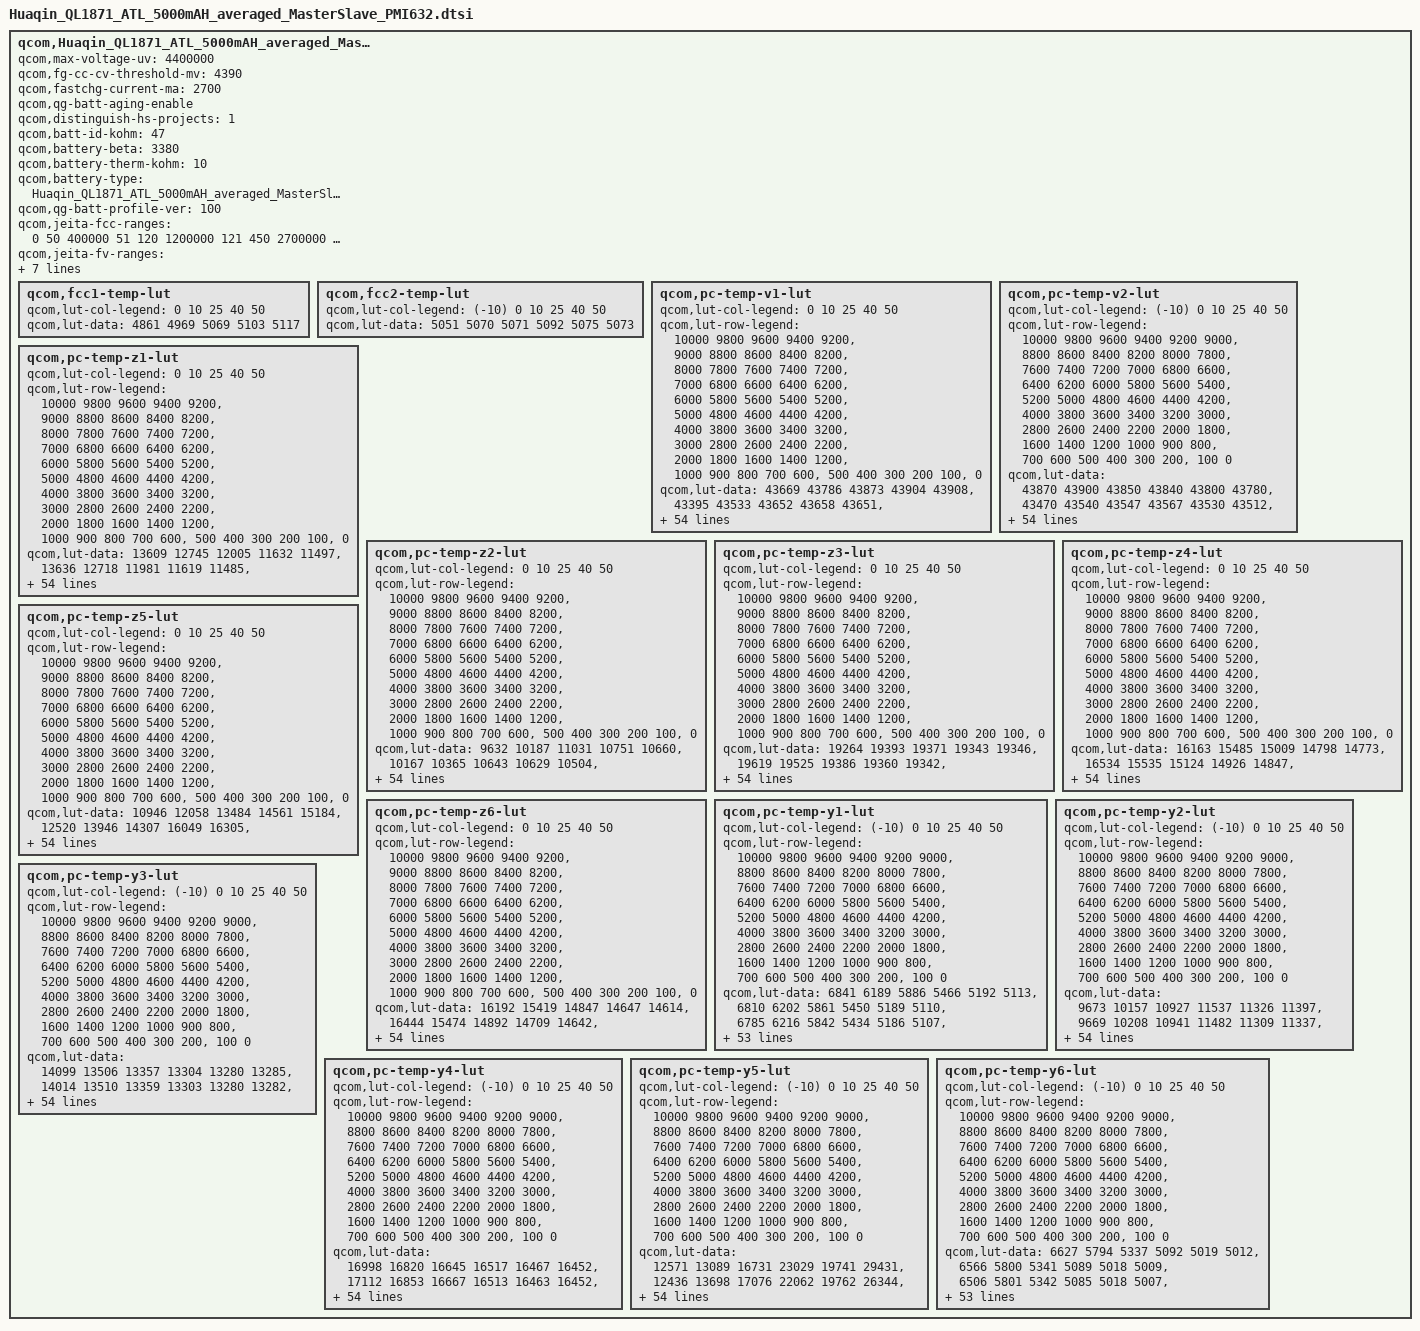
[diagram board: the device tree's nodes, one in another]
qcom,Huaqin_QL1871_ATL_5000mAH_averaged_MasterSlave_PMI632 {
        /* Huaqin_QL1871_ATL_5000mAH_averaged_MasterSlave_PMI632 */
	qcom,max-voltage-uv = <4400000>;
	qcom,fg-cc-cv-threshold-mv = <4390>;
	qcom,fastchg-current-ma = <2700>;
	/* HS60 add for SR-ZQL1695-01-357 Import battery aging by gaochao at 2019/08/29 start */
	qcom,qg-batt-aging-enable;
	/* HS60 add for SR-ZQL1695-01-357 Import battery aging by gaochao at 2019/08/29 end */
	/* HS50 add for SR-QL3095-01-67 Distinguish HS60, HS70 and HS50 charging by wenyaqi at 2020/8/3 start */
	qcom,distinguish-hs-projects = <1>;
	/* HS50 add for SR-QL3095-01-67 Distinguish HS60, HS70 and HS50 charging by wenyaqi at 2020/8/3 end */
	qcom,batt-id-kohm = <47>;
	qcom,battery-beta = <3380>;
	qcom,battery-therm-kohm = <10>;
	qcom,battery-type = "Huaqin_QL1871_ATL_5000mAH_averaged_MasterSlave_PMI632";
	qcom,qg-batt-profile-ver = <100>;

	qcom,jeita-fcc-ranges = <0   50   400000
				 51   120   1200000
				 121 450  2700000
				 451 500  2200000>;
	qcom,jeita-fv-ranges =  <0   50  4400000
				 51   120  4400000
				 121 450  4400000
				 451 500  4200000>;

	/* HS60 add for SR-ZQL1695-01-357 Import battery aging by gaochao at 2019/08/29 start */
	qcom,vfloat-ranges = <0 299 4400000
	                      300 399 4380000
                              400 699 4360000
                              700 999 4340000
                              1000 9999 4290000>;

	qcom,vbat-rechg-ranges = <0 299 4330000
                                  300 399 4310000
                                  400 699 4290000
                                  700 999 4270000
                                  1000 9999 4220000>;
	/* HS60 add for SR-ZQL1695-01-357 Import battery aging by gaochao at 2019/08/29 end */

	/* COOL = 15 DegC, WARM = 45 DegC */
	qcom,jeita-soft-thresholds = <0x2554 0xFDC>;
	/* COLD = 0 DegC, HOT = 50 DegC */
	/* Huaqin add for HS70-733 modify jeita-hard-thresholds to 50 by qianyingdong at 2019/11/26 start */
	qcom,jeita-hard-thresholds = <0x36B9 0xDBF>;
	/* Huaqin add for HS70-733 modify jeita-hard-thresholds to 50 by qianyingdong at 2019/11/26 end */

	qcom,fcc1-temp-lut {
		qcom,lut-col-legend = <0 10 25 40 50>;
		qcom,lut-data = <4861 4969 5069 5103 5117>;
	};

	qcom,fcc2-temp-lut {
		qcom,lut-col-legend = <(-10) 0 10 25 40 50>;
		qcom,lut-data = <5051 5070 5071 5092 5075 5073>;
	};

	qcom,pc-temp-v1-lut {
		qcom,lut-col-legend = <0 10 25 40 50>;
		qcom,lut-row-legend = <10000 9800 9600 9400 9200>,
			<9000 8800 8600 8400 8200>,
			<8000 7800 7600 7400 7200>,
			<7000 6800 6600 6400 6200>,
			<6000 5800 5600 5400 5200>,
			<5000 4800 4600 4400 4200>,
			<4000 3800 3600 3400 3200>,
			<3000 2800 2600 2400 2200>,
			<2000 1800 1600 1400 1200>,
			<1000 900 800 700 600>,
			<500 400 300 200 100>,
			<0>;
		qcom,lut-data = <43669 43786 43873 43904 43908>,
			<43395 43533 43652 43658 43651>,
			<43131 43284 43407 43424 43418>,
			<42875 43040 43157 43190 43187>,
			<42628 42800 42914 42954 42956>,
			<42391 42562 42672 42713 42722>,
			<42161 42325 42432 42475 42489>,
			<41938 42091 42194 42239 42253>,
			<41720 41862 41960 42006 42018>,
			<41510 41638 41728 41775 41786>,
			<41314 41422 41500 41545 41557>,
			<41121 41221 41281 41322 41333>,
			<40910 41021 41068 41104 41114>,
			<40682 40810 40862 40893 40903>,
			<40461 40591 40653 40686 40695>,
			<40250 40388 40451 40485 40494>,
			<40051 40198 40264 40293 40301>,
			<39887 40023 40091 40112 40117>,
			<39754 39868 39926 39939 39942>,
			<39627 39729 39779 39781 39780>,
			<39491 39583 39630 39630 39628>,
			<39352 39423 39428 39445 39448>,
			<39220 39254 39163 39202 39212>,
			<39094 39061 38951 38981 38990>,
			<38971 38844 38813 38827 38830>,
			<38848 38691 38701 38700 38697>,
			<38725 38606 38598 38585 38579>,
			<38615 38540 38505 38481 38473>,
			<38514 38477 38421 38388 38378>,
			<38426 38417 38346 38303 38292>,
			<38366 38364 38280 38228 38214>,
			<38321 38316 38221 38160 38142>,
			<38284 38271 38169 38100 38076>,
			<38254 38234 38126 38048 38016>,
			<38228 38203 38094 38008 37967>,
			<38203 38171 38061 37970 37919>,
			<38183 38142 38023 37922 37860>,
			<38157 38110 37981 37865 37791>,
			<38111 38056 37923 37797 37715>,
			<38040 37965 37833 37716 37634>,
			<37951 37857 37727 37620 37542>,
			<37824 37734 37614 37508 37432>,
			<37677 37592 37484 37376 37302>,
			<37512 37424 37325 37218 37144>,
			<37354 37271 37173 37078 37006>,
			<37238 37164 37076 36987 36922>,
			<37199 37131 37047 36960 36895>,
			<37169 37111 37026 36943 36879>,
			<37138 37086 37006 36924 36860>,
			<37091 37048 36967 36874 36798>,
			<36890 36825 36720 36609 36513>,
			<36442 36385 36283 36167 36068>,
			<35864 35806 35705 35588 35486>,
			<35076 35012 34913 34795 34689>,
			<33832 33775 33677 33560 33448>,
			<30000 30000 30000 30000 30000>;
	};

	qcom,pc-temp-v2-lut {
		qcom,lut-col-legend = <(-10) 0 10 25 40 50>;
		qcom,lut-row-legend = <10000 9800 9600 9400 9200 9000>,
			<8800 8600 8400 8200 8000 7800>,
			<7600 7400 7200 7000 6800 6600>,
			<6400 6200 6000 5800 5600 5400>,
			<5200 5000 4800 4600 4400 4200>,
			<4000 3800 3600 3400 3200 3000>,
			<2800 2600 2400 2200 2000 1800>,
			<1600 1400 1200 1000 900 800>,
			<700 600 500 400 300 200>,
			<100 0>;
		qcom,lut-data = <43870 43900 43850 43840 43800 43780>,
			<43470 43540 43547 43567 43530 43512>,
			<43102 43211 43261 43304 43270 43254>,
			<42766 42918 42994 43053 43023 43007>,
			<42456 42657 42745 42813 42788 42770>,
			<42184 42404 42501 42575 42554 42536>,
			<41958 42149 42257 42338 42319 42302>,
			<41750 41900 42017 42103 42084 42069>,
			<41509 41645 41783 41871 41852 41839>,
			<41233 41385 41553 41642 41623 41611>,
			<41015 41171 41329 41417 41397 41386>,
			<40893 41028 41112 41197 41176 41165>,
			<40774 40887 40900 40981 40958 40948>,
			<40513 40652 40700 40773 40749 40738>,
			<40045 40317 40509 40570 40544 40533>,
			<39685 40031 40307 40371 40348 40337>,
			<39485 39818 40088 40172 40158 40148>,
			<39319 39623 39865 39981 39975 39968>,
			<39138 39420 39645 39807 39805 39799>,
			<38958 39216 39426 39641 39643 39638>,
			<38791 39026 39221 39445 39457 39455>,
			<38632 38848 39024 39196 39223 39226>,
			<38492 38680 38845 38964 38996 39002>,
			<38381 38510 38692 38790 38816 38819>,
			<38288 38348 38555 38642 38658 38658>,
			<38209 38236 38431 38516 38525 38523>,
			<38143 38159 38319 38408 38415 38411>,
			<38083 38096 38214 38309 38316 38311>,
			<38023 38039 38111 38217 38224 38218>,
			<37964 37989 38014 38131 38139 38133>,
			<37908 37940 37942 38053 38064 38056>,
			<37852 37893 37885 37979 37996 37987>,
			<37796 37847 37837 37912 37931 37921>,
			<37737 37801 37797 37850 37868 37858>,
			<37677 37755 37761 37792 37806 37794>,
			<37614 37704 37722 37732 37728 37709>,
			<37548 37647 37683 37669 37634 37594>,
			<37479 37585 37637 37603 37540 37484>,
			<37411 37516 37576 37532 37458 37395>,
			<37342 37440 37502 37456 37378 37312>,
			<37274 37355 37416 37373 37293 37226>,
			<37208 37258 37308 37278 37204 37138>,
			<37138 37148 37174 37158 37090 37025>,
			<37062 37029 37022 37020 36958 36893>,
			<36979 36917 36891 36892 36837 36779>,
			<36880 36823 36799 36848 36801 36742>,
			<36819 36782 36760 36831 36788 36733>,
			<36746 36739 36721 36806 36773 36718>,
			<36656 36685 36664 36767 36740 36685>,
			<36512 36596 36565 36647 36629 36558>,
			<36267 36399 36292 36290 36294 36193>,
			<35871 35992 35787 35749 35769 35669>,
			<35282 35376 35114 35043 35088 34982>,
			<34393 34494 34145 34028 34114 34000>,
			<32803 33138 32773 32593 32889 32727>,
			<28390 27880 27663 27615 27964 27918>;
	};

	qcom,pc-temp-z1-lut {
		qcom,lut-col-legend = <0 10 25 40 50>;
		qcom,lut-row-legend = <10000 9800 9600 9400 9200>,
			<9000 8800 8600 8400 8200>,
			<8000 7800 7600 7400 7200>,
			<7000 6800 6600 6400 6200>,
			<6000 5800 5600 5400 5200>,
			<5000 4800 4600 4400 4200>,
			<4000 3800 3600 3400 3200>,
			<3000 2800 2600 2400 2200>,
			<2000 1800 1600 1400 1200>,
			<1000 900 800 700 600>,
			<500 400 300 200 100>,
			<0>;
		qcom,lut-data = <13609 12745 12005 11632 11497>,
			<13636 12718 11981 11619 11485>,
			<13626 12696 11971 11606 11478>,
			<13599 12680 11965 11596 11472>,
			<13577 12666 11958 11590 11468>,
			<13560 12662 11950 11586 11466>,
			<13544 12665 11942 11583 11464>,
			<13525 12669 11932 11580 11462>,
			<13503 12671 11925 11577 11461>,
			<13493 12672 11921 11575 11460>,
			<13494 12672 11918 11573 11459>,
			<13497 12667 11916 11572 11459>,
			<13490 12662 11915 11570 11459>,
			<13470 12659 11914 11569 11459>,
			<13458 12653 11910 11567 11458>,
			<13461 12650 11906 11565 11458>,
			<13470 12649 11906 11565 11457>,
			<13477 12649 11906 11566 11458>,
			<13488 12655 11908 11566 11459>,
			<13500 12671 11910 11567 11461>,
			<13512 12682 11914 11570 11463>,
			<13525 12690 11917 11572 11465>,
			<13533 12696 11921 11576 11468>,
			<13539 12696 11925 11580 11471>,
			<13544 12688 11932 11583 11473>,
			<13556 12687 11940 11587 11477>,
			<13575 12705 11945 11591 11480>,
			<13586 12725 11949 11595 11484>,
			<13594 12728 11953 11599 11487>,
			<13601 12726 11957 11603 11490>,
			<13601 12726 11962 11607 11493>,
			<13599 12730 11965 11611 11495>,
			<13597 12734 11969 11615 11498>,
			<13593 12736 11973 11619 11501>,
			<13589 12738 11978 11622 11504>,
			<13588 12740 11983 11625 11507>,
			<13600 12748 11988 11630 11511>,
			<13611 12759 11993 11636 11516>,
			<13607 12764 11999 11640 11520>,
			<13598 12768 12004 11644 11524>,
			<13601 12771 12009 11647 11527>,
			<13635 12771 12013 11650 11530>,
			<13647 12773 12017 11654 11531>,
			<13588 12782 12023 11658 11533>,
			<13624 12799 12030 11661 11535>,
			<13633 12798 12032 11663 11536>,
			<13623 12798 12035 11664 11536>,
			<13621 12793 12034 11667 11538>,
			<13632 12800 12042 11668 11540>,
			<13661 12799 12042 11674 11545>,
			<13646 12828 12057 11683 11554>,
			<13661 12842 12072 11692 11562>,
			<13681 12878 12088 11704 11572>,
			<13740 12917 12119 11726 11589>,
			<13740 12917 12119 11726 11589>,
			<13740 12917 12119 11726 11589>;
	};

	qcom,pc-temp-z2-lut {
		qcom,lut-col-legend = <0 10 25 40 50>;
		qcom,lut-row-legend = <10000 9800 9600 9400 9200>,
			<9000 8800 8600 8400 8200>,
			<8000 7800 7600 7400 7200>,
			<7000 6800 6600 6400 6200>,
			<6000 5800 5600 5400 5200>,
			<5000 4800 4600 4400 4200>,
			<4000 3800 3600 3400 3200>,
			<3000 2800 2600 2400 2200>,
			<2000 1800 1600 1400 1200>,
			<1000 900 800 700 600>,
			<500 400 300 200 100>,
			<0>;
		qcom,lut-data = <9632 10187 11031 10751 10660>,
			<10167 10365 10643 10629 10504>,
			<10260 10462 10653 10671 10541>,
			<10299 10447 10670 10718 10599>,
			<10335 10399 10683 10726 10607>,
			<10378 10382 10697 10725 10553>,
			<10410 10394 10705 10722 10505>,
			<10418 10411 10713 10709 10490>,
			<10412 10424 10720 10692 10482>,
			<10398 10436 10729 10684 10481>,
			<10356 10447 10739 10679 10485>,
			<10305 10456 10743 10671 10495>,
			<10276 10465 10740 10643 10529>,
			<10252 10473 10738 10612 10566>,
			<10241 10483 10738 10608 10564>,
			<10242 10495 10738 10616 10543>,
			<10244 10517 10741 10620 10530>,
			<10252 10539 10748 10616 10529>,
			<10284 10548 10752 10609 10531>,
			<10312 10553 10742 10597 10530>,
			<10318 10554 10728 10582 10529>,
			<10321 10533 10725 10590 10535>,
			<10323 10504 10723 10687 10577>,
			<10325 10484 10714 10760 10613>,
			<10325 10458 10678 10686 10573>,
			<10323 10446 10637 10558 10483>,
			<10317 10442 10625 10538 10437>,
			<10316 10437 10620 10573 10415>,
			<10321 10436 10618 10606 10405>,
			<10330 10435 10624 10623 10413>,
			<10340 10435 10635 10636 10430>,
			<10353 10450 10655 10640 10444>,
			<10367 10474 10689 10629 10456>,
			<10384 10494 10709 10622 10470>,
			<10402 10514 10720 10631 10504>,
			<10383 10534 10727 10650 10552>,
			<10204 10555 10739 10675 10608>,
			<10071 10576 10763 10714 10675>,
			<10135 10593 10785 10757 10700>,
			<10325 10609 10832 10818 10686>,
			<10721 10616 10866 10861 10670>,
			<12327 10612 10865 10854 10671>,
			<13431 10607 10860 10839 10678>,
			<12784 10607 10854 10861 10688>,
			<13949 10625 10855 10851 10690>,
			<14915 10651 10867 10806 10655>,
			<15695 10663 10838 10785 10693>,
			<15862 10973 10864 10815 10713>,
			<14521 10840 10847 10820 10736>,
			<14391 11070 11035 10893 10804>,
			<14562 11062 10989 10855 10593>,
			<13524 10968 10939 10746 10499>,
			<13135 10648 10833 10721 10446>,
			<11894 10622 10747 10612 10327>,
			<11894 10622 10747 10612 10327>,
			<11894 10622 10747 10612 10327>;
	};

	qcom,pc-temp-z3-lut {
		qcom,lut-col-legend = <0 10 25 40 50>;
		qcom,lut-row-legend = <10000 9800 9600 9400 9200>,
			<9000 8800 8600 8400 8200>,
			<8000 7800 7600 7400 7200>,
			<7000 6800 6600 6400 6200>,
			<6000 5800 5600 5400 5200>,
			<5000 4800 4600 4400 4200>,
			<4000 3800 3600 3400 3200>,
			<3000 2800 2600 2400 2200>,
			<2000 1800 1600 1400 1200>,
			<1000 900 800 700 600>,
			<500 400 300 200 100>,
			<0>;
		qcom,lut-data = <19264 19393 19371 19343 19346>,
			<19619 19525 19386 19360 19342>,
			<19714 19608 19434 19375 19356>,
			<19766 19631 19461 19383 19363>,
			<19775 19643 19458 19384 19364>,
			<19733 19645 19449 19383 19358>,
			<19691 19627 19441 19380 19354>,
			<19689 19606 19433 19375 19353>,
			<19696 19594 19427 19368 19353>,
			<19701 19585 19426 19364 19352>,
			<19716 19575 19425 19362 19351>,
			<19732 19564 19422 19360 19349>,
			<19732 19554 19414 19353 19345>,
			<19719 19548 19408 19347 19340>,
			<19709 19545 19406 19346 19338>,
			<19704 19539 19404 19346 19337>,
			<19695 19524 19400 19347 19336>,
			<19682 19511 19387 19346 19336>,
			<19647 19509 19379 19345 19335>,
			<19622 19510 19379 19345 19334>,
			<19623 19511 19379 19346 19332>,
			<19628 19521 19387 19349 19333>,
			<19633 19535 19419 19367 19350>,
			<19637 19548 19436 19381 19365>,
			<19643 19561 19438 19378 19365>,
			<19655 19566 19439 19374 19363>,
			<19677 19567 19439 19373 19362>,
			<19691 19567 19437 19375 19361>,
			<19700 19566 19435 19376 19359>,
			<19707 19560 19433 19375 19354>,
			<19704 19556 19431 19373 19347>,
			<19692 19551 19429 19371 19345>,
			<19677 19544 19426 19368 19343>,
			<19664 19536 19421 19365 19342>,
			<19647 19527 19412 19357 19338>,
			<19611 19521 19404 19350 19335>,
			<19515 19515 19402 19349 19335>,
			<19440 19510 19402 19349 19335>,
			<19388 19506 19402 19349 19336>,
			<19295 19502 19400 19348 19336>,
			<19261 19499 19398 19347 19335>,
			<19258 19498 19395 19347 19333>,
			<19257 19496 19391 19347 19331>,
			<19258 19493 19387 19350 19338>,
			<19257 19475 19385 19347 19341>,
			<19257 19463 19375 19339 19332>,
			<19257 19453 19372 19336 19330>,
			<19257 19359 19370 19327 19318>,
			<19257 19321 19367 19327 19315>,
			<19257 19262 19335 19321 19316>,
			<19257 19330 19357 19329 19331>,
			<19257 19294 19354 19330 19333>,
			<19257 19300 19352 19335 19337>,
			<19258 19354 19357 19333 19343>,
			<19258 19354 19357 19333 19343>,
			<19258 19354 19357 19333 19343>;
	};

	qcom,pc-temp-z4-lut {
		qcom,lut-col-legend = <0 10 25 40 50>;
		qcom,lut-row-legend = <10000 9800 9600 9400 9200>,
			<9000 8800 8600 8400 8200>,
			<8000 7800 7600 7400 7200>,
			<7000 6800 6600 6400 6200>,
			<6000 5800 5600 5400 5200>,
			<5000 4800 4600 4400 4200>,
			<4000 3800 3600 3400 3200>,
			<3000 2800 2600 2400 2200>,
			<2000 1800 1600 1400 1200>,
			<1000 900 800 700 600>,
			<500 400 300 200 100>,
			<0>;
		qcom,lut-data = <16163 15485 15009 14798 14773>,
			<16534 15535 15124 14926 14847>,
			<16475 15545 15076 14897 14840>,
			<16286 15473 15011 14845 14809>,
			<16109 15278 14955 14820 14793>,
			<15951 15140 14900 14808 14786>,
			<15795 15058 14867 14798 14780>,
			<15639 14999 14848 14788 14772>,
			<15481 14961 14833 14780 14765>,
			<15363 14932 14816 14771 14758>,
			<15284 14914 14801 14763 14751>,
			<15223 14902 14791 14755 14744>,
			<15173 14892 14785 14749 14737>,
			<15132 14878 14778 14743 14729>,
			<15099 14863 14770 14735 14722>,
			<15073 14851 14762 14726 14716>,
			<15050 14843 14756 14717 14709>,
			<15033 14836 14751 14709 14701>,
			<15020 14822 14746 14702 14694>,
			<15007 14802 14740 14695 14688>,
			<14991 14795 14734 14690 14683>,
			<14973 14809 14770 14700 14687>,
			<14962 14836 14918 14789 14755>,
			<14956 14901 14994 14856 14813>,
			<14951 15029 14952 14844 14806>,
			<14952 15086 14890 14816 14785>,
			<14963 15034 14854 14795 14771>,
			<14973 14959 14829 14778 14760>,
			<14985 14916 14811 14764 14751>,
			<14997 14884 14799 14753 14743>,
			<14995 14862 14790 14744 14735>,
			<14978 14847 14784 14738 14728>,
			<14959 14836 14780 14734 14720>,
			<14943 14828 14774 14729 14714>,
			<14928 14821 14765 14721 14706>,
			<14932 14815 14759 14715 14700>,
			<15001 14805 14759 14720 14705>,
			<15056 14797 14760 14734 14726>,
			<15091 14797 14763 14741 14735>,
			<15169 14803 14772 14742 14733>,
			<15195 14806 14779 14743 14731>,
			<15192 14796 14768 14738 14725>,
			<15188 14786 14752 14729 14717>,
			<15184 14785 14754 14735 14728>,
			<15151 14778 14750 14736 14732>,
			<15130 14757 14727 14717 14706>,
			<15120 14752 14711 14706 14695>,
			<15104 14831 14691 14689 14682>,
			<15091 14858 14676 14663 14657>,
			<15078 14911 14699 14666 14657>,
			<15076 14858 14707 14692 14682>,
			<15114 14910 14715 14697 14688>,
			<15134 14910 14721 14694 14686>,
			<15163 14871 14721 14698 14682>,
			<15163 14871 14721 14698 14682>,
			<15163 14871 14721 14698 14682>;
	};

	qcom,pc-temp-z5-lut {
		qcom,lut-col-legend = <0 10 25 40 50>;
		qcom,lut-row-legend = <10000 9800 9600 9400 9200>,
			<9000 8800 8600 8400 8200>,
			<8000 7800 7600 7400 7200>,
			<7000 6800 6600 6400 6200>,
			<6000 5800 5600 5400 5200>,
			<5000 4800 4600 4400 4200>,
			<4000 3800 3600 3400 3200>,
			<3000 2800 2600 2400 2200>,
			<2000 1800 1600 1400 1200>,
			<1000 900 800 700 600>,
			<500 400 300 200 100>,
			<0>;
		qcom,lut-data = <10946 12058 13484 14561 15184>,
			<12520 13946 14307 16049 16305>,
			<13244 15353 16099 17697 18134>,
			<13726 16179 17514 18859 19684>,
			<13939 16761 18248 19391 19944>,
			<14012 17255 18754 19723 19396>,
			<14076 17775 18859 19837 19004>,
			<14237 18202 18825 19460 19226>,
			<14561 18489 18799 18970 19654>,
			<14867 18760 19124 18937 19934>,
			<15136 18832 19715 19027 20161>,
			<15387 18648 19767 19049 20252>,
			<15570 18460 19220 18426 19832>,
			<15727 18688 18843 17747 19284>,
			<15811 19358 19059 17934 19279>,
			<15963 19608 19403 18614 19558>,
			<16190 18988 19261 18948 19937>,
			<16151 18317 18228 19378 20635>,
			<15677 18490 17606 19935 21429>,
			<15296 19405 17822 20726 22059>,
			<15502 20636 18326 21795 22631>,
			<16096 23060 19364 21913 22633>,
			<16681 25227 21550 20496 20747>,
			<17175 25177 22577 18965 18822>,
			<17799 24208 20900 17980 18180>,
			<19076 23299 18842 17213 17776>,
			<21280 22238 18843 17259 17821>,
			<22756 21331 19752 18333 18628>,
			<23858 21386 20808 19520 19189>,
			<24709 22064 22046 20440 19054>,
			<24413 22637 23388 21318 18839>,
			<23267 23516 24734 22241 18978>,
			<22095 24546 26087 23344 19926>,
			<21168 24883 26460 23814 20989>,
			<20118 24715 25661 23505 22181>,
			<18736 24580 24893 23142 23135>,
			<16645 24448 25262 23352 23215>,
			<15134 24259 26229 23966 23147>,
			<13963 24209 26574 24162 23041>,
			<12001 24147 26415 23422 22795>,
			<11317 24134 26085 22703 22428>,
			<11316 24279 25543 22841 21705>,
			<11314 24387 24673 23134 20848>,
			<11306 23741 23080 22789 21764>,
			<11283 21329 22783 21189 21824>,
			<11243 20015 21167 19578 19418>,
			<11211 19016 21235 19417 19334>,
			<11163 13368 21589 18577 17923>,
			<11160 12708 21905 20752 20105>,
			<11175 11405 16341 19634 20451>,
			<11221 12559 17918 17018 18558>,
			<11188 11885 16921 16520 17502>,
			<11112 11861 16132 16497 17348>,
			<11014 12520 15997 15564 17178>,
			<11014 12520 15997 15564 17178>,
			<11014 12520 15997 15564 17178>;
	};

	qcom,pc-temp-z6-lut {
		qcom,lut-col-legend = <0 10 25 40 50>;
		qcom,lut-row-legend = <10000 9800 9600 9400 9200>,
			<9000 8800 8600 8400 8200>,
			<8000 7800 7600 7400 7200>,
			<7000 6800 6600 6400 6200>,
			<6000 5800 5600 5400 5200>,
			<5000 4800 4600 4400 4200>,
			<4000 3800 3600 3400 3200>,
			<3000 2800 2600 2400 2200>,
			<2000 1800 1600 1400 1200>,
			<1000 900 800 700 600>,
			<500 400 300 200 100>,
			<0>;
		qcom,lut-data = <16192 15419 14847 14647 14614>,
			<16444 15474 14892 14709 14642>,
			<16412 15488 14884 14700 14643>,
			<16303 15452 14871 14682 14635>,
			<16190 15350 14848 14671 14627>,
			<16066 15270 14813 14664 14621>,
			<15945 15215 14791 14657 14616>,
			<15849 15173 14777 14649 14611>,
			<15766 15145 14766 14642 14608>,
			<15713 15124 14757 14636 14604>,
			<15686 15108 14749 14631 14600>,
			<15665 15096 14741 14625 14596>,
			<15637 15085 14734 14619 14591>,
			<15603 15071 14727 14613 14585>,
			<15575 15056 14722 14608 14581>,
			<15559 15043 14717 14605 14577>,
			<15547 15032 14711 14601 14574>,
			<15533 15024 14702 14597 14570>,
			<15517 15019 14697 14593 14567>,
			<15506 15014 14695 14591 14564>,
			<15505 15013 14694 14589 14561>,
			<15505 15026 14714 14595 14564>,
			<15506 15050 14796 14645 14604>,
			<15509 15089 14839 14683 14639>,
			<15515 15155 14823 14677 14636>,
			<15526 15184 14799 14663 14626>,
			<15546 15165 14785 14655 14620>,
			<15562 15137 14774 14649 14615>,
			<15578 15120 14767 14644 14610>,
			<15590 15106 14761 14639 14604>,
			<15590 15097 14757 14634 14598>,
			<15582 15090 14754 14631 14593>,
			<15572 15084 14752 14628 14590>,
			<15563 15079 14748 14624 14586>,
			<15552 15074 14740 14617 14581>,
			<15542 15071 14735 14611 14577>,
			<15530 15069 14735 14613 14579>,
			<15522 15067 14737 14620 14589>,
			<15519 15069 14739 14624 14593>,
			<15516 15076 14744 14625 14593>,
			<15517 15080 14748 14625 14592>,
			<15524 15081 14743 14623 14589>,
			<15531 15082 14736 14620 14585>,
			<15539 15086 14738 14625 14594>,
			<15536 15082 14737 14625 14597>,
			<15534 15074 14723 14613 14582>,
			<15533 15069 14716 14606 14576>,
			<15528 15059 14707 14594 14565>,
			<15527 15056 14701 14584 14552>,
			<15530 15057 14697 14583 14554>,
			<15545 15078 14716 14600 14574>,
			<15578 15095 14722 14606 14580>,
			<15612 15113 14729 14610 14584>,
			<15662 15146 14740 14615 14589>,
			<15662 15146 14740 14615 14589>,
			<15662 15146 14740 14615 14589>;
	};

	qcom,pc-temp-y1-lut {
		qcom,lut-col-legend = <(-10) 0 10 25 40 50>;
		qcom,lut-row-legend = <10000 9800 9600 9400 9200 9000>,
			<8800 8600 8400 8200 8000 7800>,
			<7600 7400 7200 7000 6800 6600>,
			<6400 6200 6000 5800 5600 5400>,
			<5200 5000 4800 4600 4400 4200>,
			<4000 3800 3600 3400 3200 3000>,
			<2800 2600 2400 2200 2000 1800>,
			<1600 1400 1200 1000 900 800>,
			<700 600 500 400 300 200>,
			<100 0>;
		qcom,lut-data = <6841 6189 5886 5466 5192 5113>,
			<6810 6202 5861 5450 5189 5110>,
			<6785 6216 5842 5434 5186 5107>,
			<6768 6230 5828 5420 5182 5105>,
			<6758 6240 5820 5408 5179 5102>,
			<6755 6243 5817 5398 5176 5101>,
			<6771 6239 5822 5390 5173 5099>,
			<6793 6233 5829 5384 5170 5099>,
			<6790 6226 5825 5382 5168 5097>,
			<6767 6212 5808 5379 5166 5095>,
			<6754 6205 5795 5378 5164 5094>,
			<6764 6206 5785 5376 5161 5093>,
			<6775 6208 5777 5372 5159 5092>,
			<6766 6214 5779 5367 5158 5092>,
			<6750 6232 5787 5360 5158 5092>,
			<6745 6237 5791 5357 5157 5092>,
			<6775 6212 5796 5357 5157 5092>,
			<6809 6187 5802 5357 5156 5092>,
			<6806 6194 5804 5355 5156 5092>,
			<6786 6218 5809 5351 5156 5093>,
			<6777 6231 5809 5350 5156 5093>,
			<6779 6238 5801 5354 5158 5094>,
			<6781 6241 5795 5359 5159 5094>,
			<6782 6237 5799 5360 5160 5095>,
			<6784 6231 5808 5362 5161 5096>,
			<6782 6230 5811 5364 5162 5098>,
			<6774 6235 5806 5369 5164 5099>,
			<6767 6239 5802 5373 5167 5101>,
			<6761 6240 5807 5375 5171 5103>,
			<6751 6242 5815 5377 5174 5105>,
			<6740 6235 5815 5380 5177 5108>,
			<6718 6223 5801 5387 5180 5110>,
			<6701 6216 5790 5392 5182 5112>,
			<6708 6219 5798 5397 5186 5114>,
			<6724 6225 5813 5401 5189 5116>,
			<6729 6220 5825 5400 5192 5118>,
			<6726 6193 5838 5398 5195 5120>,
			<6722 6176 5845 5397 5197 5121>,
			<6735 6184 5845 5405 5199 5123>,
			<6759 6197 5845 5414 5201 5126>,
			<6757 6202 5840 5414 5203 5127>,
			<6718 6217 5823 5411 5205 5128>,
			<6704 6227 5819 5419 5208 5130>,
			<6703 6231 5822 5429 5211 5132>,
			<6731 6220 5844 5435 5217 5137>,
			<6757 6231 5854 5448 5223 5140>,
			<6776 6208 5860 5445 5223 5141>,
			<6774 6240 5833 5452 5224 5140>,
			<6690 6248 5847 5460 5225 5141>,
			<6714 6221 5842 5456 5224 5142>,
			<6735 6210 5850 5467 5227 5144>,
			<6767 6213 5854 5492 5236 5151>,
			<6734 6228 5888 5508 5249 5160>,
			<6770 6251 5903 5534 5262 5171>,
			<6770 6251 5903 5534 5262 5171>,
			<6770 6251 5903 5534 5262 5171>;
	};

	qcom,pc-temp-y2-lut {
		qcom,lut-col-legend = <(-10) 0 10 25 40 50>;
		qcom,lut-row-legend = <10000 9800 9600 9400 9200 9000>,
			<8800 8600 8400 8200 8000 7800>,
			<7600 7400 7200 7000 6800 6600>,
			<6400 6200 6000 5800 5600 5400>,
			<5200 5000 4800 4600 4400 4200>,
			<4000 3800 3600 3400 3200 3000>,
			<2800 2600 2400 2200 2000 1800>,
			<1600 1400 1200 1000 900 800>,
			<700 600 500 400 300 200>,
			<100 0>;
		qcom,lut-data = <9673 10157 10927 11537 11326 11397>,
			<9669 10208 10941 11482 11309 11337>,
			<9667 10296 10949 11426 11288 11281>,
			<9669 10393 10952 11375 11265 11228>,
			<9673 10472 10953 11331 11245 11181>,
			<9680 10506 10952 11298 11230 11140>,
			<9834 10508 10945 11274 11208 11101>,
			<10042 10508 10935 11255 11183 11069>,
			<10020 10548 10935 11239 11173 11050>,
			<9805 10689 10940 11225 11164 11031>,
			<9696 10778 10948 11216 11159 11024>,
			<10071 10800 10962 11210 11148 11037>,
			<10545 10816 10985 11206 11136 11051>,
			<10452 10851 11031 11212 11134 11045>,
			<9928 10903 11108 11233 11133 11022>,
			<9678 10945 11145 11261 11139 11014>,
			<9678 10973 11144 11311 11178 11054>,
			<9678 10996 11139 11371 11242 11121>,
			<9677 11019 11149 11438 11340 11207>,
			<9674 11041 11172 11507 11473 11317>,
			<9672 11047 11181 11518 11518 11349>,
			<9671 11041 11180 11471 11480 11329>,
			<9671 11033 11181 11434 11443 11308>,
			<9670 10862 11199 11451 11445 11298>,
			<9670 10490 11239 11489 11453 11289>,
			<9669 10337 11271 11518 11455 11289>,
			<9668 10009 11295 11543 11462 11307>,
			<9667 9741 11318 11564 11471 11330>,
			<9666 9726 11346 11581 11490 11347>,
			<9665 9716 11373 11596 11521 11365>,
			<9664 9705 11387 11610 11554 11396>,
			<9663 9694 11396 11626 11600 11458>,
			<9663 9686 11400 11633 11633 11510>,
			<9662 9680 11373 11625 11647 11540>,
			<9661 9675 11314 11616 11656 11562>,
			<9661 9671 11262 11615 11641 11557>,
			<9660 9668 11212 11615 11565 11514>,
			<9660 9666 11159 11611 11519 11470>,
			<9660 9664 11100 11596 11519 11427>,
			<9659 9662 11035 11581 11523 11386>,
			<9659 9661 10964 11577 11520 11376>,
			<9659 9660 10878 11573 11509 11375>,
			<9659 9659 10480 11549 11507 11360>,
			<9658 9658 9856 11490 11505 11336>,
			<9658 9658 9748 11401 11472 11306>,
			<9658 9657 9724 11374 11384 11217>,
			<9657 9657 9703 11361 11428 11170>,
			<9657 9657 9692 11331 11443 11194>,
			<9657 9656 9684 11337 11456 11258>,
			<9657 9656 9680 11329 11432 11227>,
			<9656 9656 9675 11241 11346 11067>,
			<9656 9655 9668 11116 11217 10998>,
			<9655 9655 9662 11011 11147 10908>,
			<9654 9654 9658 10907 11038 10766>,
			<9654 9654 9658 10907 11038 10766>,
			<9654 9654 9658 10907 11038 10766>;
	};

	qcom,pc-temp-y3-lut {
		qcom,lut-col-legend = <(-10) 0 10 25 40 50>;
		qcom,lut-row-legend = <10000 9800 9600 9400 9200 9000>,
			<8800 8600 8400 8200 8000 7800>,
			<7600 7400 7200 7000 6800 6600>,
			<6400 6200 6000 5800 5600 5400>,
			<5200 5000 4800 4600 4400 4200>,
			<4000 3800 3600 3400 3200 3000>,
			<2800 2600 2400 2200 2000 1800>,
			<1600 1400 1200 1000 900 800>,
			<700 600 500 400 300 200>,
			<100 0>;
		qcom,lut-data = <14099 13506 13357 13304 13280 13285>,
			<14014 13510 13359 13303 13280 13282>,
			<13930 13511 13362 13302 13281 13279>,
			<13853 13510 13365 13301 13281 13278>,
			<13786 13507 13367 13300 13282 13277>,
			<13734 13503 13369 13300 13283 13277>,
			<13698 13497 13371 13300 13283 13277>,
			<13667 13490 13373 13301 13284 13279>,
			<13628 13487 13373 13301 13284 13280>,
			<13580 13485 13373 13301 13285 13281>,
			<13543 13481 13373 13302 13285 13282>,
			<13518 13454 13372 13304 13285 13283>,
			<13500 13426 13370 13307 13285 13283>,
			<13493 13424 13368 13307 13286 13283>,
			<13489 13427 13365 13307 13287 13283>,
			<13485 13427 13362 13307 13287 13283>,
			<13479 13419 13359 13306 13288 13285>,
			<13472 13406 13356 13305 13290 13287>,
			<13464 13397 13350 13306 13290 13288>,
			<13455 13388 13344 13307 13291 13289>,
			<13447 13381 13339 13307 13291 13289>,
			<13437 13374 13334 13303 13288 13285>,
			<13431 13368 13331 13298 13285 13281>,
			<13431 13351 13329 13294 13283 13279>,
			<13433 13326 13328 13291 13282 13277>,
			<13437 13313 13327 13290 13281 13277>,
			<13453 13295 13325 13291 13280 13277>,
			<13475 13283 13323 13292 13279 13277>,
			<13493 13285 13319 13291 13279 13276>,
			<13511 13292 13313 13291 13278 13275>,
			<13534 13301 13310 13291 13278 13275>,
			<13566 13317 13309 13291 13279 13275>,
			<13601 13338 13308 13291 13279 13276>,
			<13638 13360 13311 13292 13280 13277>,
			<13677 13385 13315 13292 13281 13277>,
			<13715 13412 13319 13292 13281 13277>,
			<13753 13441 13323 13291 13279 13276>,
			<13791 13475 13326 13291 13278 13275>,
			<13830 13516 13328 13290 13278 13276>,
			<13869 13563 13330 13290 13278 13276>,
			<13912 13612 13333 13290 13278 13276>,
			<13960 13666 13337 13291 13279 13277>,
			<14009 13722 13338 13292 13279 13277>,
			<14059 13778 13340 13292 13278 13277>,
			<14111 13816 13357 13290 13276 13275>,
			<14125 13856 13369 13294 13281 13277>,
			<14185 13909 13385 13296 13284 13283>,
			<14250 13957 13406 13298 13288 13286>,
			<14329 14009 13431 13304 13291 13288>,
			<14413 14063 13469 13307 13290 13286>,
			<14511 14122 13490 13304 13286 13283>,
			<14642 14203 13529 13307 13286 13284>,
			<14843 14336 13655 13316 13290 13288>,
			<15349 14506 13862 13332 13296 13292>,
			<15349 14506 13862 13332 13296 13292>,
			<15349 14506 13862 13332 13296 13292>;
	};

	qcom,pc-temp-y4-lut {
		qcom,lut-col-legend = <(-10) 0 10 25 40 50>;
		qcom,lut-row-legend = <10000 9800 9600 9400 9200 9000>,
			<8800 8600 8400 8200 8000 7800>,
			<7600 7400 7200 7000 6800 6600>,
			<6400 6200 6000 5800 5600 5400>,
			<5200 5000 4800 4600 4400 4200>,
			<4000 3800 3600 3400 3200 3000>,
			<2800 2600 2400 2200 2000 1800>,
			<1600 1400 1200 1000 900 800>,
			<700 600 500 400 300 200>,
			<100 0>;
		qcom,lut-data = <16998 16820 16645 16517 16467 16452>,
			<17112 16853 16667 16513 16463 16452>,
			<17207 16914 16695 16510 16460 16452>,
			<17279 16983 16723 16508 16459 16452>,
			<17323 17039 16744 16506 16458 16453>,
			<17338 17062 16752 16506 16458 16453>,
			<17308 17065 16747 16507 16459 16454>,
			<17268 17067 16742 16508 16461 16455>,
			<17285 17059 16742 16511 16464 16455>,
			<17378 17029 16745 16515 16467 16457>,
			<17428 17017 16749 16520 16471 16458>,
			<17425 17137 16758 16524 16476 16461>,
			<17418 17277 16772 16530 16482 16466>,
			<17345 17229 16799 16539 16488 16471>,
			<17113 17033 16842 16555 16495 16477>,
			<16987 16924 16857 16573 16502 16483>,
			<16972 16900 16832 16595 16511 16488>,
			<16961 16881 16793 16616 16522 16494>,
			<16935 16848 16755 16636 16543 16507>,
			<16893 16805 16712 16654 16572 16528>,
			<16859 16762 16671 16650 16579 16534>,
			<16830 16716 16630 16579 16546 16519>,
			<16810 16679 16596 16513 16505 16498>,
			<16803 16658 16577 16492 16480 16477>,
			<16799 16640 16562 16479 16459 16457>,
			<16796 16639 16551 16477 16455 16452>,
			<16789 16669 16542 16478 16457 16454>,
			<16784 16694 16533 16480 16461 16456>,
			<16787 16696 16522 16483 16466 16461>,
			<16793 16700 16512 16487 16474 16468>,
			<16795 16700 16510 16492 16482 16477>,
			<16793 16695 16513 16497 16493 16486>,
			<16791 16692 16517 16500 16501 16494>,
			<16791 16693 16521 16503 16506 16502>,
			<16792 16696 16528 16505 16510 16508>,
			<16793 16699 16538 16503 16506 16504>,
			<16796 16704 16555 16494 16483 16479>,
			<16802 16709 16572 16487 16468 16463>,
			<16810 16714 16586 16482 16464 16461>,
			<16824 16718 16597 16479 16462 16460>,
			<16838 16718 16600 16482 16464 16462>,
			<16855 16715 16600 16488 16469 16469>,
			<16876 16710 16607 16491 16469 16468>,
			<16898 16704 16626 16490 16463 16460>,
			<16903 16706 16632 16475 16448 16442>,
			<16845 16701 16640 16488 16457 16457>,
			<16859 16716 16670 16504 16470 16476>,
			<16876 16740 16708 16527 16495 16510>,
			<16892 16775 16757 16566 16531 16542>,
			<16897 16813 16801 16582 16529 16529>,
			<16887 16823 16808 16540 16480 16468>,
			<16875 16787 16802 16546 16471 16463>,
			<16879 16770 16843 16582 16482 16468>,
			<16997 16779 16911 16654 16523 16503>,
			<16997 16779 16911 16654 16523 16503>,
			<16997 16779 16911 16654 16523 16503>;
	};

	qcom,pc-temp-y5-lut {
		qcom,lut-col-legend = <(-10) 0 10 25 40 50>;
		qcom,lut-row-legend = <10000 9800 9600 9400 9200 9000>,
			<8800 8600 8400 8200 8000 7800>,
			<7600 7400 7200 7000 6800 6600>,
			<6400 6200 6000 5800 5600 5400>,
			<5200 5000 4800 4600 4400 4200>,
			<4000 3800 3600 3400 3200 3000>,
			<2800 2600 2400 2200 2000 1800>,
			<1600 1400 1200 1000 900 800>,
			<700 600 500 400 300 200>,
			<100 0>;
		qcom,lut-data = <12571 13089 16731 23029 19741 29431>,
			<12436 13698 17076 22062 19762 26344>,
			<12467 14489 17420 20989 19650 23288>,
			<12632 15297 17745 19917 19437 20586>,
			<12899 15962 18031 18958 19152 18564>,
			<13242 16320 18259 18219 18826 17549>,
			<14721 16479 18473 17617 18420 17537>,
			<16513 16570 18627 17082 17944 17844>,
			<16262 16549 18575 16566 17439 17988>,
			<14198 16431 18246 15962 16864 18308>,
			<13147 16378 17816 15740 16330 18295>,
			<16467 16612 17063 15943 15800 17757>,
			<20652 17109 16401 16164 15355 17056>,
			<19905 18310 16711 15959 15128 16384>,
			<15521 20661 18035 15352 15019 15686>,
			<13438 21587 19250 15134 14989 15462>,
			<13683 21330 20367 15248 14892 15725>,
			<13965 21063 21223 15489 14861 16022>,
			<13971 21152 21521 16874 15055 16082>,
			<13882 21468 21705 19820 15419 16103>,
			<13733 21723 21794 21768 16218 16320>,
			<13223 21958 21835 23135 19402 18165>,
			<12655 22107 21912 23825 22138 20173>,
			<12387 20347 22284 22511 22427 21056>,
			<12190 16164 22945 20107 22465 21664>,
			<12143 14086 23277 19711 22175 21698>,
			<12284 12839 23430 20621 20667 20731>,
			<12419 12113 23500 21261 19247 19494>,
			<12403 12077 21951 21278 18615 18293>,
			<12348 12042 18784 21270 18151 17170>,
			<12345 12062 17350 21351 18131 16963>,
			<12521 12291 16684 21633 18612 17161>,
			<12711 12600 16401 22061 19311 17499>,
			<12801 12969 17112 23175 20572 18581>,
			<12880 13364 18520 24312 21931 20053>,
			<12877 13574 19515 24428 22118 20548>,
			<12754 13705 20424 24384 21904 20745>,
			<12622 13783 20943 24277 21598 20815>,
			<12508 13819 21054 23190 21053 20637>,
			<12384 13838 21074 21909 20405 20366>,
			<12370 13863 21069 21571 19968 20261>,
			<12480 13909 20985 21427 19652 20250>,
			<12593 13854 18774 20894 19968 20843>,
			<12715 13574 14610 20683 20410 21627>,
			<12958 13084 14133 20133 18504 19164>,
			<13188 13057 14100 19725 19558 16982>,
			<13207 13342 13953 19222 19439 18559>,
			<13343 13485 14294 18196 19768 18007>,
			<13782 13686 14679 18632 18999 17442>,
			<14018 13958 15444 19319 18601 17300>,
			<13991 14055 14986 20020 18960 18173>,
			<13520 13664 13876 19807 19650 19530>,
			<13034 13228 13460 20511 20593 21060>,
			<12374 13166 13288 21801 23203 23850>,
			<12374 13166 13288 21801 23203 23850>,
			<12374 13166 13288 21801 23203 23850>;
	};

	qcom,pc-temp-y6-lut {
		qcom,lut-col-legend = <(-10) 0 10 25 40 50>;
		qcom,lut-row-legend = <10000 9800 9600 9400 9200 9000>,
			<8800 8600 8400 8200 8000 7800>,
			<7600 7400 7200 7000 6800 6600>,
			<6400 6200 6000 5800 5600 5400>,
			<5200 5000 4800 4600 4400 4200>,
			<4000 3800 3600 3400 3200 3000>,
			<2800 2600 2400 2200 2000 1800>,
			<1600 1400 1200 1000 900 800>,
			<700 600 500 400 300 200>,
			<100 0>;
		qcom,lut-data = <6627 5794 5337 5092 5019 5012>,
			<6566 5800 5341 5089 5018 5009>,
			<6506 5801 5342 5085 5018 5007>,
			<6449 5797 5342 5082 5018 5006>,
			<6399 5789 5340 5079 5018 5005>,
			<6358 5780 5338 5077 5019 5005>,
			<6326 5766 5333 5076 5019 5006>,
			<6297 5750 5327 5075 5020 5007>,
			<6262 5732 5322 5075 5021 5008>,
			<6215 5712 5319 5076 5022 5009>,
			<6195 5704 5316 5076 5023 5010>,
			<6198 5716 5315 5078 5024 5011>,
			<6202 5731 5314 5081 5026 5013>,
			<6175 5717 5316 5084 5028 5014>,
			<6074 5668 5324 5087 5030 5016>,
			<6015 5635 5327 5091 5033 5018>,
			<6004 5622 5318 5096 5036 5020>,
			<5997 5612 5304 5102 5040 5023>,
			<5988 5599 5289 5108 5047 5028>,
			<5978 5585 5272 5113 5055 5035>,
			<5971 5573 5257 5112 5057 5037>,
			<5964 5563 5242 5089 5045 5029>,
			<5960 5554 5230 5067 5031 5019>,
			<5962 5544 5225 5058 5022 5012>,
			<5969 5535 5222 5052 5015 5005>,
			<5978 5534 5220 5052 5014 5004>,
			<5991 5544 5219 5053 5014 5004>,
			<6007 5559 5218 5055 5015 5005>,
			<6025 5575 5216 5056 5016 5006>,
			<6046 5594 5213 5058 5018 5008>,
			<6070 5616 5213 5059 5021 5010>,
			<6096 5642 5218 5062 5025 5013>,
			<6125 5671 5225 5064 5028 5016>,
			<6155 5704 5234 5066 5030 5019>,
			<6186 5740 5247 5068 5032 5022>,
			<6217 5779 5262 5067 5031 5021>,
			<6248 5819 5281 5065 5024 5013>,
			<6281 5861 5302 5064 5019 5008>,
			<6314 5907 5324 5064 5018 5008>,
			<6349 5954 5349 5063 5018 5008>,
			<6385 6002 5376 5065 5018 5009>,
			<6424 6050 5405 5069 5021 5012>,
			<6466 6096 5435 5074 5021 5011>,
			<6513 6142 5468 5075 5020 5009>,
			<6561 6178 5502 5073 5015 5003>,
			<6575 6215 5532 5082 5022 5010>,
			<6624 6260 5571 5090 5028 5019>,
			<6680 6304 5617 5100 5038 5031>,
			<6745 6355 5666 5117 5050 5042>,
			<6812 6409 5720 5125 5049 5037>,
			<6889 6458 5762 5114 5032 5018>,
			<6995 6514 5834 5124 5031 5018>,
			<7159 6615 5987 5152 5039 5023>,
			<7643 6756 6192 5196 5057 5039>,
			<7643 6756 6192 5196 5057 5039>,
			<7643 6756 6192 5196 5057 5039>;
	};

};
